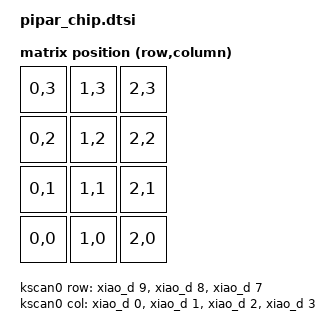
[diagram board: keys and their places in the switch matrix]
/*
 * Copyright (c) 2022 The ZMK Contributors
 *
 * SPDX-License-Identifier: MIT
 */

#include <dt-bindings/zmk/matrix_transform.h>

/ {
  chosen {
    zmk,kscan = &kscan0;
    zmk,matrix-transform = &default_transform;
    zmk,backlight = &backlight;
  };

  kscan0: kscan_0 {
    compatible = "zmk,kscan-gpio-matrix";
    diode-direction = "col2row";
    wakeup-source;

    row-gpios
      = <&xiao_d 9 (GPIO_ACTIVE_HIGH | GPIO_PULL_DOWN)>
      , <&xiao_d 8 (GPIO_ACTIVE_HIGH | GPIO_PULL_DOWN)>
      , <&xiao_d 7 (GPIO_ACTIVE_HIGH | GPIO_PULL_DOWN)>
      ;

    col-gpios
      = <&xiao_d 0 GPIO_ACTIVE_HIGH>
      , <&xiao_d 1 GPIO_ACTIVE_HIGH>
      , <&xiao_d 2 GPIO_ACTIVE_HIGH>
      , <&xiao_d 3 GPIO_ACTIVE_HIGH>
      ;
    };

  default_transform: keymap_transform_0 {
    compatible = "zmk,matrix-transform";
    rows = <3>;
    columns = <4>;
    map = <
      RC(0, 3) RC(1, 3) RC(2, 3)
      RC(0, 2) RC(1, 2) RC(2, 2)
      RC(0, 1) RC(1, 1) RC(2, 1)
      RC(0, 0) RC(1, 0) RC(2, 0)  
    >;
  };

  
  backlight: pwmleds {
      compatible = "pwm-leds";
      pwm_led_0 {
          pwms = <&pwm0 0 PWM_MSEC(10) PWM_POLARITY_NORMAL>;
      };
  };

};

&pwm0 {
    status = "okay";
    pinctrl-0 = <&pwm0_default>;
    pinctrl-1 = <&pwm0_sleep>;
    pinctrl-names = "default", "sleep";
};
